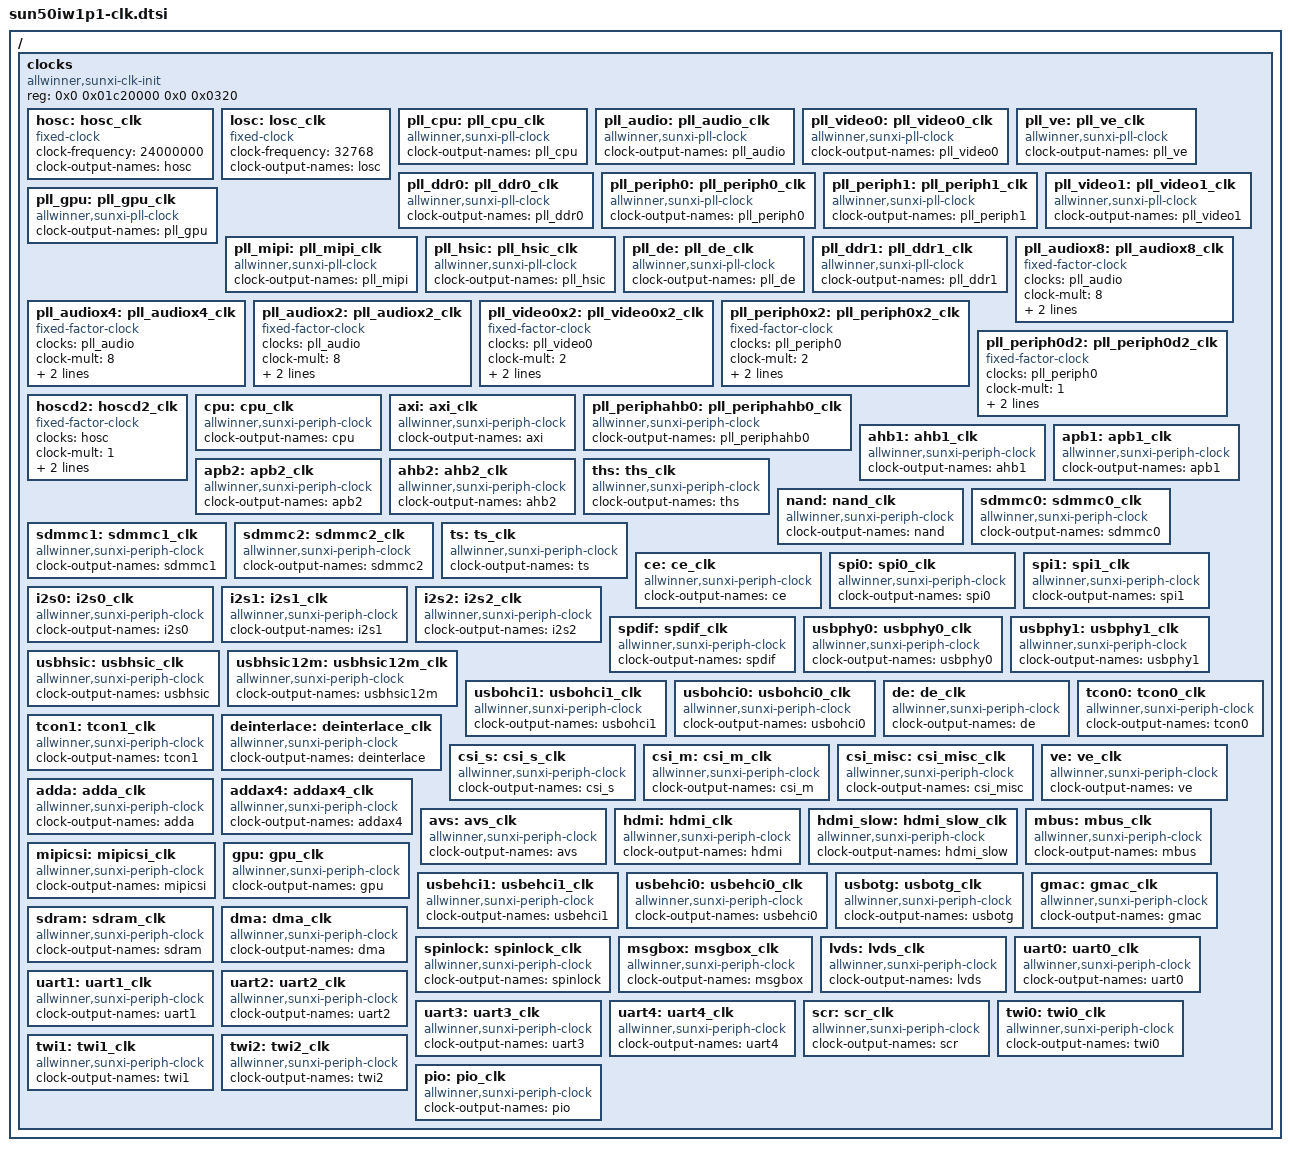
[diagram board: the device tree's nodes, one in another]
/{
clocks {
	compatible = "allwinner,sunxi-clk-init";
	#address-cells = <2>;
	#size-cells = <2>;
	ranges;
	reg = <0x0 0x01c20000 0x0 0x0320>;
	
/* register fixed rate clock*/
		hosc: hosc_clk {
			#clock-cells = <0>;
			compatible = "fixed-clock";
			clock-frequency = <24000000>;
			clock-output-names = "hosc";
		};

		losc: losc_clk {
			#clock-cells = <0>;
			compatible = "fixed-clock";
			clock-frequency = <32768>;
			clock-output-names = "losc";
		};
			
/* register allwinner,sunxi-pll-clock */
		pll_cpu: pll_cpu_clk {
			#clock-cells = <0>;
			compatible = "allwinner,sunxi-pll-clock";
			clock-output-names = "pll_cpu";
		};
		pll_audio: pll_audio_clk {
			#clock-cells = <0>;
			compatible = "allwinner,sunxi-pll-clock";
			clock-output-names = "pll_audio";
		};	
		pll_video0: pll_video0_clk {
			#clock-cells = <0>;
			compatible = "allwinner,sunxi-pll-clock";
			clock-output-names = "pll_video0";
		};		
		pll_ve: pll_ve_clk {
			#clock-cells = <0>;
			compatible = "allwinner,sunxi-pll-clock";
			clock-output-names = "pll_ve";
		};		
		pll_ddr0: pll_ddr0_clk {
			#clock-cells = <0>;
			compatible = "allwinner,sunxi-pll-clock";
			clock-output-names = "pll_ddr0";
		};			
		pll_periph0: pll_periph0_clk {
			#clock-cells = <0>;
			compatible = "allwinner,sunxi-pll-clock";
			clock-output-names = "pll_periph0";
		};			
		pll_periph1: pll_periph1_clk {
			#clock-cells = <0>;
			compatible = "allwinner,sunxi-pll-clock";
			clock-output-names = "pll_periph1";
		};		
		pll_video1: pll_video1_clk {
			#clock-cells = <0>;
			compatible = "allwinner,sunxi-pll-clock";
			clock-output-names = "pll_video1";
		};			
		pll_gpu: pll_gpu_clk {
			#clock-cells = <0>;
			compatible = "allwinner,sunxi-pll-clock";
			clock-output-names = "pll_gpu";
		};		
		pll_mipi: pll_mipi_clk {
			#clock-cells = <0>;
			compatible = "allwinner,sunxi-pll-clock";
			clock-output-names = "pll_mipi";
		};		
		pll_hsic: pll_hsic_clk {
			#clock-cells = <0>;
			compatible = "allwinner,sunxi-pll-clock";
			clock-output-names = "pll_hsic";
		};		
		pll_de: pll_de_clk {
			#clock-cells = <0>;
			compatible = "allwinner,sunxi-pll-clock";
			clock-output-names = "pll_de";
		};	
		pll_ddr1: pll_ddr1_clk {
			#clock-cells = <0>;
			compatible = "allwinner,sunxi-pll-clock";
			clock-output-names = "pll_ddr1";
		};		
/* register fixed factor clock*/
		pll_audiox8: pll_audiox8_clk {
			#clock-cells = <0>;
			compatible = "fixed-factor-clock";
			clocks = <&pll_audio>;
			clock-mult = <8>;
			clock-div = <1>;
			clock-output-names = "pll_audiox8";
		};
		pll_audiox4: pll_audiox4_clk {
			#clock-cells = <0>;
			compatible = "fixed-factor-clock";
			clocks = <&pll_audio>;
			clock-mult = <8>;
			clock-div = <2>;
			clock-output-names = "pll_audiox4";
		};
		pll_audiox2: pll_audiox2_clk {
			#clock-cells = <0>;
			compatible = "fixed-factor-clock";
			clocks = <&pll_audio>;
			clock-mult = <8>;
			clock-div = <4>;
			clock-output-names = "pll_audiox2";
		};
		pll_video0x2: pll_video0x2_clk {
			#clock-cells = <0>;
			compatible = "fixed-factor-clock";
			clocks = <&pll_video0>;
			clock-mult = <2>;
			clock-div = <1>;
			clock-output-names = "pll_video0x2";
		};		
		pll_periph0x2: pll_periph0x2_clk {
			#clock-cells = <0>;
			compatible = "fixed-factor-clock";
			clocks = <&pll_periph0>;
			clock-mult = <2>;
			clock-div = <1>;
			clock-output-names = "pll_periph0x2";
		};	
		pll_periph0d2: pll_periph0d2_clk {
			#clock-cells = <0>;
			compatible = "fixed-factor-clock";
			clocks = <&pll_periph0>;
			clock-mult = <1>;
			clock-div = <2>;
			clock-output-names = "pll_periph0d2";
		};	
		hoscd2: hoscd2_clk {
			#clock-cells = <0>;
			compatible = "fixed-factor-clock";
			clocks = <&hosc>;
			clock-mult = <1>;
			clock-div = <2>;
			clock-output-names = "hoscd2";
		};	
/* register allwinner,sunxi-periph-clock */
		cpu: cpu_clk {
			#clock-cells = <0>;
			compatible = "allwinner,sunxi-periph-clock";
			clock-output-names = "cpu";
		};	
		axi: axi_clk {
			#clock-cells = <0>;
			compatible = "allwinner,sunxi-periph-clock";
			clock-output-names = "axi";
		};		
		pll_periphahb0: pll_periphahb0_clk {
			#clock-cells = <0>;
			compatible = "allwinner,sunxi-periph-clock";
			clock-output-names = "pll_periphahb0";
		};	
		ahb1: ahb1_clk {
			#clock-cells = <0>;
			compatible = "allwinner,sunxi-periph-clock";
			clock-output-names = "ahb1";
		};	
		apb1: apb1_clk {
			#clock-cells = <0>;
			compatible = "allwinner,sunxi-periph-clock";
			clock-output-names = "apb1";
		};	
		apb2: apb2_clk {
			#clock-cells = <0>;
			compatible = "allwinner,sunxi-periph-clock";
			clock-output-names = "apb2";
		};	
		ahb2: ahb2_clk {
			#clock-cells = <0>;
			compatible = "allwinner,sunxi-periph-clock";
			clock-output-names = "ahb2";
		};	
		ths: ths_clk {
			#clock-cells = <0>;
			compatible = "allwinner,sunxi-periph-clock";
			clock-output-names = "ths";
		};	
		nand: nand_clk {
			#clock-cells = <0>;
			compatible = "allwinner,sunxi-periph-clock";
			clock-output-names = "nand";
		};	
		sdmmc0: sdmmc0_clk {
			#clock-cells = <0>;
			compatible = "allwinner,sunxi-periph-clock";
			clock-output-names = "sdmmc0";
		};	
		sdmmc1: sdmmc1_clk {
			#clock-cells = <0>;
			compatible = "allwinner,sunxi-periph-clock";
			clock-output-names = "sdmmc1";
		};	
		sdmmc2: sdmmc2_clk {
			#clock-cells = <0>;
			compatible = "allwinner,sunxi-periph-clock";
			clock-output-names = "sdmmc2";
		};		
		ts: ts_clk {
			#clock-cells = <0>;
			compatible = "allwinner,sunxi-periph-clock";
			clock-output-names = "ts";
		};		
		ce: ce_clk {
			#clock-cells = <0>;
			compatible = "allwinner,sunxi-periph-clock";
			clock-output-names = "ce";
		};		
		spi0: spi0_clk {
			#clock-cells = <0>;
			compatible = "allwinner,sunxi-periph-clock";
			clock-output-names = "spi0";
		};	
		spi1: spi1_clk {
			#clock-cells = <0>;
			compatible = "allwinner,sunxi-periph-clock";
			clock-output-names = "spi1";
		};	
		i2s0: i2s0_clk {
			#clock-cells = <0>;
			compatible = "allwinner,sunxi-periph-clock";
			clock-output-names = "i2s0";
		};	
		i2s1: i2s1_clk {
			#clock-cells = <0>;
			compatible = "allwinner,sunxi-periph-clock";
			clock-output-names = "i2s1";
		};	
		i2s2: i2s2_clk {
			#clock-cells = <0>;
			compatible = "allwinner,sunxi-periph-clock";
			clock-output-names = "i2s2";
		};		
		spdif: spdif_clk {
			#clock-cells = <0>;
			compatible = "allwinner,sunxi-periph-clock";
			clock-output-names = "spdif";
		};	
		usbphy0: usbphy0_clk {
			#clock-cells = <0>;
			compatible = "allwinner,sunxi-periph-clock";
			clock-output-names = "usbphy0";
		};	
		usbphy1: usbphy1_clk {
			#clock-cells = <0>;
			compatible = "allwinner,sunxi-periph-clock";
			clock-output-names = "usbphy1";
		};	
		usbhsic: usbhsic_clk {
			#clock-cells = <0>;
			compatible = "allwinner,sunxi-periph-clock";
			clock-output-names = "usbhsic";
		};	
		usbhsic12m: usbhsic12m_clk {
			#clock-cells = <0>;
			compatible = "allwinner,sunxi-periph-clock";
			clock-output-names = "usbhsic12m";
		};		
		usbohci1: usbohci1_clk {
			#clock-cells = <0>;
			compatible = "allwinner,sunxi-periph-clock";
			clock-output-names = "usbohci1";
		};	
		usbohci0: usbohci0_clk {
			#clock-cells = <0>;
			compatible = "allwinner,sunxi-periph-clock";
			clock-output-names = "usbohci0";
		};		
		de: de_clk {
			#clock-cells = <0>;
			compatible = "allwinner,sunxi-periph-clock";
			clock-output-names = "de";
		};
		tcon0: tcon0_clk {
			#clock-cells = <0>;
			compatible = "allwinner,sunxi-periph-clock";
			clock-output-names = "tcon0";
		};
		tcon1: tcon1_clk {
			#clock-cells = <0>;
			compatible = "allwinner,sunxi-periph-clock";
			clock-output-names = "tcon1";
		};	
		deinterlace: deinterlace_clk {
			#clock-cells = <0>;
			compatible = "allwinner,sunxi-periph-clock";
			clock-output-names = "deinterlace";
		};	
		csi_s: csi_s_clk {
			#clock-cells = <0>;
			compatible = "allwinner,sunxi-periph-clock";
			clock-output-names = "csi_s";
		};	
		csi_m: csi_m_clk {
			#clock-cells = <0>;
			compatible = "allwinner,sunxi-periph-clock";
			clock-output-names = "csi_m";
		};		
		csi_misc: csi_misc_clk {
			#clock-cells = <0>;
			compatible = "allwinner,sunxi-periph-clock";
			clock-output-names = "csi_misc";
		};	
		ve: ve_clk {
			#clock-cells = <0>;
			compatible = "allwinner,sunxi-periph-clock";
			clock-output-names = "ve";
		};	
		adda: adda_clk {
			#clock-cells = <0>;
			compatible = "allwinner,sunxi-periph-clock";
			clock-output-names = "adda";
		};	
		addax4: addax4_clk {
			#clock-cells = <0>;
			compatible = "allwinner,sunxi-periph-clock";
			clock-output-names = "addax4";
		};	
		avs: avs_clk {
			#clock-cells = <0>;
			compatible = "allwinner,sunxi-periph-clock";
			clock-output-names = "avs";
		};	
		hdmi: hdmi_clk {
			#clock-cells = <0>;
			compatible = "allwinner,sunxi-periph-clock";
			clock-output-names = "hdmi";
		};	
		hdmi_slow: hdmi_slow_clk {
			#clock-cells = <0>;
			compatible = "allwinner,sunxi-periph-clock";
			clock-output-names = "hdmi_slow";
		};	
		mbus: mbus_clk {
			#clock-cells = <0>;
			compatible = "allwinner,sunxi-periph-clock";
			clock-output-names = "mbus";
		};	
		mipicsi: mipicsi_clk {
			#clock-cells = <0>;
			compatible = "allwinner,sunxi-periph-clock";
			clock-output-names = "mipicsi";
		};		
		gpu: gpu_clk {
			#clock-cells = <0>;
			compatible = "allwinner,sunxi-periph-clock";
			clock-output-names = "gpu";
		};	
		usbehci1: usbehci1_clk {
			#clock-cells = <0>;
			compatible = "allwinner,sunxi-periph-clock";
			clock-output-names = "usbehci1";
		};	
		usbehci0: usbehci0_clk {
			#clock-cells = <0>;
			compatible = "allwinner,sunxi-periph-clock";
			clock-output-names = "usbehci0";
		};	
		usbotg: usbotg_clk {
			#clock-cells = <0>;
			compatible = "allwinner,sunxi-periph-clock";
			clock-output-names = "usbotg";
		};	
		gmac: gmac_clk {
			#clock-cells = <0>;
			compatible = "allwinner,sunxi-periph-clock";
			clock-output-names = "gmac";
		};	
		sdram: sdram_clk {
			#clock-cells = <0>;
			compatible = "allwinner,sunxi-periph-clock";
			clock-output-names = "sdram";
		};	
		dma: dma_clk {
			#clock-cells = <0>;
			compatible = "allwinner,sunxi-periph-clock";
			clock-output-names = "dma";
		};	
		spinlock: spinlock_clk {
			#clock-cells = <0>;
			compatible = "allwinner,sunxi-periph-clock";
			clock-output-names = "spinlock";
		};	
		msgbox: msgbox_clk {
			#clock-cells = <0>;
			compatible = "allwinner,sunxi-periph-clock";
			clock-output-names = "msgbox";
		};	
		lvds: lvds_clk {
			#clock-cells = <0>;
			compatible = "allwinner,sunxi-periph-clock";
			clock-output-names = "lvds";
		};	
		uart0: uart0_clk {
			#clock-cells = <0>;
			compatible = "allwinner,sunxi-periph-clock";
			clock-output-names = "uart0";
		};		
		uart1: uart1_clk {
			#clock-cells = <0>;
			compatible = "allwinner,sunxi-periph-clock";
			clock-output-names = "uart1";
		};	
		uart2: uart2_clk {
			#clock-cells = <0>;
			compatible = "allwinner,sunxi-periph-clock";
			clock-output-names = "uart2";
		};	
		uart3: uart3_clk {
			#clock-cells = <0>;
			compatible = "allwinner,sunxi-periph-clock";
			clock-output-names = "uart3";
		};		
		uart4: uart4_clk {
			#clock-cells = <0>;
			compatible = "allwinner,sunxi-periph-clock";
			clock-output-names = "uart4";
		};	
		scr: scr_clk {
			#clock-cells = <0>;
			compatible = "allwinner,sunxi-periph-clock";
			clock-output-names = "scr";
		};	
		twi0: twi0_clk {
			#clock-cells = <0>;
			compatible = "allwinner,sunxi-periph-clock";
			clock-output-names = "twi0";
		};	
		twi1: twi1_clk {
			#clock-cells = <0>;
			compatible = "allwinner,sunxi-periph-clock";
			clock-output-names = "twi1";
		};	
		twi2: twi2_clk {
			#clock-cells = <0>;
			compatible = "allwinner,sunxi-periph-clock";
			clock-output-names = "twi2";
		};	
		pio: pio_clk {
			#clock-cells = <0>;
			compatible = "allwinner,sunxi-periph-clock";
			clock-output-names = "pio";
		};	
	};/*end*/
};
